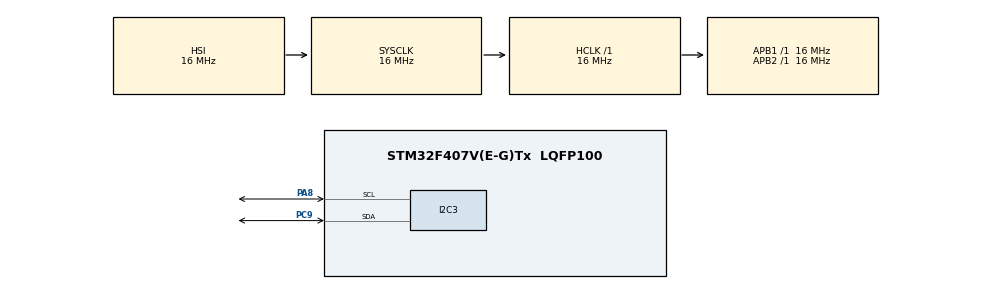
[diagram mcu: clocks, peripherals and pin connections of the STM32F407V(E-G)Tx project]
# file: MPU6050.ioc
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Mcu.Family=STM32F4
Mcu.Name=STM32F407V(E-G)Tx
Mcu.Package=LQFP100
NVIC.PriorityGroup=NVIC_PRIORITYGROUP_4
PA13.Mode=Serial_Wire
PA13.Signal=SYS_JTMS-SWDIO
PA14.Mode=Serial_Wire
PA14.Signal=SYS_JTCK-SWCLK
PA8.Mode=I2C
PA8.Signal=I2C3_SCL
PC9.Mode=I2C
PC9.Signal=I2C3_SDA
ProjectManager.HeapSize=0x200
ProjectManager.StackSize=0x400
ProjectManager.TargetToolchain=STM32CubeIDE
RCC.AHBFreq_Value=16000000
RCC.APB1Freq_Value=16000000
RCC.APB2Freq_Value=16000000
RCC.CortexFreq_Value=16000000
RCC.HSE_VALUE=25000000
RCC.HSI_VALUE=16000000
RCC.LSE_VALUE=32768
RCC.SYSCLKFreq_VALUE=16000000
RCC.VCOOutputFreq_Value=192000000
board=custom

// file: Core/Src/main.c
/* USER CODE BEGIN Header */
/**
  ******************************************************************************
  * @file           : main.c
  * @brief          : Main program body
  ******************************************************************************
  * @attention
  *
  * Copyright (c) 2024 STMicroelectronics.
  * All rights reserved.
  *
  * This software is licensed under terms that can be found in the LICENSE file
  * in the root directory of this software component.
  * If no LICENSE file comes with this software, it is provided AS-IS.
  *
  ******************************************************************************
  */
/* USER CODE END Header */
#include "main.h"

/* USER CODE BEGIN PD */
#define MPU6050_ADDRESS 0x68 << 1
#define PWR_MGMT_1 0x6B
#define ACCEL_XOUT_H 0x3B
#define GYRO_XOUT_H 0x43
/* USER CODE END PD */

I2C_HandleTypeDef hi2c3;

void SystemClock_Config(void);
static void MX_GPIO_Init(void);
static void MX_I2C3_Init(void);

/* USER CODE BEGIN 0 */
void MPU6050_Init(void) {
    uint8_t check;
    uint8_t Data;

    HAL_I2C_Mem_Read(&hi2c3, MPU6050_ADDRESS, PWR_MGMT_1, I2C_MEMADD_SIZE_8BIT, &check, 1, HAL_MAX_DELAY);
    if (check == 0x68) {

        Data = 0;
        HAL_I2C_Mem_Write(&hi2c3, MPU6050_ADDRESS, PWR_MGMT_1, I2C_MEMADD_SIZE_8BIT, &Data, 1, HAL_MAX_DELAY);
    }
}
void MPU6050_Read_Gyroscope(int16_t *gyro_x, int16_t *gyro_y, int16_t *gyro_z) {
    uint8_t data[6];
    HAL_I2C_Mem_Read(&hi2c3, MPU6050_ADDRESS, GYRO_XOUT_H, I2C_MEMADD_SIZE_8BIT, data, 6, HAL_MAX_DELAY);

    *gyro_x = (int16_t)((data[0] << 8) | data[1]);
    *gyro_y = (int16_t)((data[2] << 8) | data[3]);
    *gyro_z = (int16_t)((data[4] << 8) | data[5]);
}

/* USER CODE END 0 */

int main(void)
{

  /* MCU Configuration--------------------------------------------------------*/

  /* Reset of all peripherals, Initializes the Flash interface and the Systick. */
  HAL_Init();

  /* USER CODE BEGIN Init */

	MPU6050_Init();

  /* USER CODE END Init */

  /* Configure the system clock */
  SystemClock_Config();

  /* Initialize all configured peripherals */
  MX_GPIO_Init();
  MX_I2C3_Init();
  /* USER CODE BEGIN 2 */
	int16_t accel_x, accel_y, accel_z;
	int16_t gyro_x, gyro_y, gyro_z;

  /* USER CODE END 2 */

  /* Infinite loop */
  /* USER CODE BEGIN WHILE */
  while (1)
  {
	  MPU6050_Read_Gyroscope(&gyro_x, &gyro_y, &gyro_z);
	  HAL_Delay(100);
    /* USER CODE END WHILE */

  }
}

void SystemClock_Config(void)
{
  RCC_OscInitTypeDef RCC_OscInitStruct = {0};
  RCC_ClkInitTypeDef RCC_ClkInitStruct = {0};

  /** Configure the main internal regulator output voltage
  */
  __HAL_RCC_PWR_CLK_ENABLE();
  __HAL_PWR_VOLTAGESCALING_CONFIG(PWR_REGULATOR_VOLTAGE_SCALE1);

  /** Initializes the RCC Oscillators according to the specified parameters
  * in the RCC_OscInitTypeDef structure.
  */
  RCC_OscInitStruct.OscillatorType = RCC_OSCILLATORTYPE_HSI;
  RCC_OscInitStruct.HSIState = RCC_HSI_ON;
  RCC_OscInitStruct.HSICalibrationValue = RCC_HSICALIBRATION_DEFAULT;
  RCC_OscInitStruct.PLL.PLLState = RCC_PLL_NONE;
  if (HAL_RCC_OscConfig(&RCC_OscInitStruct) != HAL_OK)
  {
    Error_Handler();
  }

  /** Initializes the CPU, AHB and APB buses clocks
  */
  RCC_ClkInitStruct.ClockType = RCC_CLOCKTYPE_HCLK|RCC_CLOCKTYPE_SYSCLK
                              |RCC_CLOCKTYPE_PCLK1|RCC_CLOCKTYPE_PCLK2;
  RCC_ClkInitStruct.SYSCLKSource = RCC_SYSCLKSOURCE_HSI;
  RCC_ClkInitStruct.AHBCLKDivider = RCC_SYSCLK_DIV1;
  RCC_ClkInitStruct.APB1CLKDivider = RCC_HCLK_DIV1;
  RCC_ClkInitStruct.APB2CLKDivider = RCC_HCLK_DIV1;

  if (HAL_RCC_ClockConfig(&RCC_ClkInitStruct, FLASH_LATENCY_0) != HAL_OK)
  {
    Error_Handler();
  }
}

static void MX_I2C3_Init(void)
{

  hi2c3.Instance = I2C3;
  hi2c3.Init.ClockSpeed = 100000;
  hi2c3.Init.DutyCycle = I2C_DUTYCYCLE_2;
  hi2c3.Init.OwnAddress1 = 0;
  hi2c3.Init.AddressingMode = I2C_ADDRESSINGMODE_7BIT;
  hi2c3.Init.DualAddressMode = I2C_DUALADDRESS_DISABLE;
  hi2c3.Init.OwnAddress2 = 0;
  hi2c3.Init.GeneralCallMode = I2C_GENERALCALL_DISABLE;
  hi2c3.Init.NoStretchMode = I2C_NOSTRETCH_DISABLE;
  if (HAL_I2C_Init(&hi2c3) != HAL_OK)
  {
    Error_Handler();
  }

}

static void MX_GPIO_Init(void)
{

  /* GPIO Ports Clock Enable */
  __HAL_RCC_GPIOC_CLK_ENABLE();
  __HAL_RCC_GPIOA_CLK_ENABLE();

}

void Error_Handler(void)
{
  __disable_irq();
  while (1)
  {
  }
}
